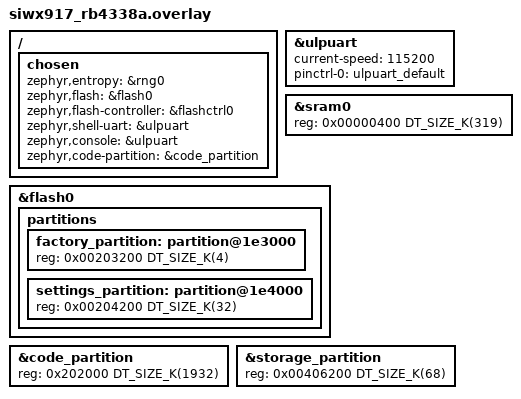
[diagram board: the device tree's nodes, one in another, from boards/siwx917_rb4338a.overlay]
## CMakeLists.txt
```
#
# Copyright (c) 2025 Project CHIP Authors
#
# Licensed under the Apache License, Version 2.0 (the "License");
# you may not use this file except in compliance with the License.
# You may obtain a copy of the License at
#
# http://www.apache.org/licenses/LICENSE-2.0
#
# Unless required by applicable law or agreed to in writing, software
# distributed under the License is distributed on an "AS IS" BASIS,
# WITHOUT WARRANTIES OR CONDITIONS OF ANY KIND, either express or implied.
# See the License for the specific language governing permissions and
# limitations under the License.
#
cmake_minimum_required(VERSION 3.13.1)

get_filename_component(CHIP_ROOT ${CMAKE_CURRENT_SOURCE_DIR}/../third_party/connectedhomeip REALPATH)
get_filename_component(GEN_DIR ${CHIP_ROOT}/zzz_generated/ REALPATH)
get_filename_component(ZEPHYR_PLATFORM_COMMON ${CHIP_ROOT}/examples/platform/silabs/zephyr REALPATH)
get_filename_component(SILABS_LIGHTING_COMMON ${CHIP_ROOT}/examples/lighting-app/silabs REALPATH)
get_filename_component(ALL_CLUSTERS_COMMON_DIR ${CHIP_ROOT}/examples/all-clusters-app/all-clusters-common REALPATH)


# Need this as wiseconnect abstraction is causing a build failure
add_definitions(-DMBEDTLS_X509_REMOVE_INFO )

list(APPEND ZEPHYR_EXTRA_MODULES ${CHIP_ROOT}/config/silabs)
find_package(Zephyr HINTS $ENV{ZEPHYR_BASE})

# -Wmaybe-uninitialized has too many false positives, including on std::optional
# and chip::Optional.  Make it nonfatal.
#
# See https://gcc.gnu.org/bugzilla/show_bug.cgi?id=80635
target_compile_options(app PRIVATE -Werror -Wno-error=maybe-uninitialized)
target_compile_options(app PRIVATE -Werror -Wno-error=format)

project(matter-zephyr-light)

include(${CHIP_ROOT}/config/silabs/app/enable-gnu-std.cmake)
include(${CHIP_ROOT}/src/app/chip_data_model.cmake)

target_include_directories(app
    PRIVATE
    include
    ${ZEPHYR_PLATFORM_COMMON}
)

target_sources(app
    PRIVATE
    src/AppTask.cpp
    src/DeviceCallbacks.cpp
    ../include/CHIPProjectConfig.h
    ${ZEPHYR_PLATFORM_COMMON}/main.cpp
    ${ZEPHYR_PLATFORM_COMMON}/AppTaskBase.cpp
    ${ZEPHYR_PLATFORM_COMMON}/AppTaskZephyr.cpp
    ${ZEPHYR_PLATFORM_COMMON}/CHIPDeviceManager.cpp
    ${ZEPHYR_PLATFORM_COMMON}/CommonDeviceCallbacks.cpp
    ${ZEPHYR_PLATFORM_COMMON}/ZclCallbacks.cpp
)

# TODO Implement OTA support
if(CONFIG_CHIP_OTA_REQUESTOR)
    # target_sources(app PRIVATE
    #                 ${EXAMPLE_PLATFORM_SILABS_COMMON_DIR}/ota_requestor/source/OTARequestorInitiatorCommon.cpp
    #                 ${EXAMPLE_PLATFORM_SILABS_COMMON_DIR}/ota_requestor/source/OTARequestorInitiatorZephyr.cpp
    # )
    # target_include_directories(app PRIVATE
    #                 ${EXAMPLE_PLATFORM_SILABS_COMMON_DIR}/ota_requestor/include/
    # )
endif()

if(CONFIG_CHIP_WIFI)
  chip_configure_data_model(app INCLUDE_SERVER
      ZAP_FILE ${SILABS_LIGHTING_COMMON}/data_model/lighting-wifi-app.zap
  )
else()
  chip_configure_data_model(app INCLUDE_SERVER
      ZAP_FILE ${SILABS_LIGHTING_COMMON}/data_model/lighting-thread-app.zap
  )
endif()

if(CONFIG_CHIP_LIB_SHELL)
    target_compile_definitions(app PRIVATE ENABLE_CHIP_SHELL)
    target_include_directories(app PRIVATE 
                               ${CHIP_ROOT}/examples/shell/shell_common/include
                               ${ZEPHYR_PLATFORM_COMMON}/include
    )
    target_sources(app PRIVATE
                   ${ZEPHYR_PLATFORM_COMMON}/AppCLIZephyr.cpp
                   ${CHIP_ROOT}/examples/shell/shell_common/cmd_misc.cpp
                   ${CHIP_ROOT}/examples/shell/shell_common/cmd_otcli.cpp
                   ${CHIP_ROOT}/examples/shell/shell_common/cmd_server.cpp
    )
endif()
```

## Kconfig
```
#
#    Copyright (c) 2025 Project CHIP Authors
#
#    Licensed under the Apache License, Version 2.0 (the "License");
#    you may not use this file except in compliance with the License.
#    You may obtain a copy of the License at
#
#        http://www.apache.org/licenses/LICENSE-2.0
#
#    Unless required by applicable law or agreed to in writing, software
#    distributed under the License is distributed on an "AS IS" BASIS,
#    WITHOUT WARRANTIES OR CONDITIONS OF ANY KIND, either express or implied.
#    See the License for the specific language governing permissions and
#    limitations under the License.
#
mainmenu "Matter Silabs Lighting Example Application"

# Sample configuration used for Thread networking
if NET_L2_OPENTHREAD
choice OPENTHREAD_DEVICE_TYPE
	default OPENTHREAD_FTD
endchoice
endif # NET_L2_OPENTHREAD

choice POSIX_AEP_CHOICE
	default POSIX_AEP_CHOICE_BASE
endchoice

rsource "../../../../config/silabs/Kconfig.defaults"
rsource "../../../../config/silabs/Kconfig"
source "Kconfig.zephyr"
```

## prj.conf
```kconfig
#
#    Copyright (c) 2025 Project CHIP Authors
#
#    Licensed under the Apache License, Version 2.0 (the "License");
#    you may not use this file except in compliance with the License.
#    You may obtain a copy of the License at
#
#        http://www.apache.org/licenses/LICENSE-2.0
#
#    Unless required by applicable law or agreed to in writing, software
#    distributed under the License is distributed on an "AS IS" BASIS,
#    WITHOUT WARRANTIES OR CONDITIONS OF ANY KIND, either express or implied.
#    See the License for the specific language governing permissions and
#    limitations under the License.
#

# This sample uses Kconfig.defaults to set options common for all
# samples. This file should contain only options specific for this sample
# or overrides of default values.

# Enable CHIP
CONFIG_CHIP=y
CONFIG_CHIP_PROJECT_CONFIG="../include/CHIPProjectConfig.h"
# 32773 == 0x8005 (example lighting-app)
CONFIG_CHIP_DEVICE_PRODUCT_ID=32773
CONFIG_STD_CPP17=y

CONFIG_GPIO=y

# Enable Matter extended announcement and increase duration to 1 hour.
CONFIG_CHIP_ENABLE_PAIRING_AUTOSTART=y
CONFIG_CHIP_BLE_EXT_ADVERTISING=y
CONFIG_CHIP_BLE_ADVERTISING_DURATION=60
CONFIG_MATTER_LOG_LEVEL_ERR=y

CONFIG_LOG_MODE_MINIMAL=n
CONFIG_LOG_MODE_DEFERRED=y
CONFIG_LOG_BUFFER_SIZE=8192

# CONFIG_IEEE802154_SILABS_EFR32_DRIVER_LOG_LEVEL=3
# CONFIG_OPENTHREAD_DEBUG=y
# CONFIG_OPENTHREAD_LOG_LEVEL_DEBG=y

CONFIG_OPENTHREAD_MANUAL_START=y
CONFIG_OPENTHREAD_OPERATIONAL_DATASET_AUTO_INIT=n
#CONFIG_OPENTHREAD_DEBUG=y
CONFIG_OPENTHREAD_LOG_LEVEL_INFO=y
CONFIG_OPENTHREAD_MLR=y
CONFIG_OPENTHREAD_SLAAC=y
CONFIG_OPENTHREAD_ENABLE_SERVICE=y
CONFIG_OPENTHREAD_THREAD_PREEMPTIVE=y
CONFIG_CHIP_TASK_PRIORITY=10
CONFIG_DNS_SD=y

# Needed for 917
CONFIG_NVS_INIT_BAD_MEMORY_REGION=y

CONFIG_SYSTEM_WORKQUEUE_STACK_SIZE=4096
CONFIG_MAIN_STACK_SIZE=8192
CONFIG_MBEDTLS_HEAP_SIZE=16384
CONFIG_SHELL_STACK_SIZE=4096
CONFIG_SHELL_THREAD_PRIORITY_OVERRIDE=y
CONFIG_SHELL_THREAD_PRIORITY=11
CONFIG_SHELL_BACKEND_SERIAL_LOG_MESSAGE_QUEUE_SIZE=2048

CONFIG_LOG_PROCESS_THREAD_CUSTOM_PRIORITY=y
CONFIG_LOG_PROCESS_THREAD_PRIORITY=12

CONFIG_UART_ASYNC_API=y

#CONFIG_MBEDTLS_CIPHER_GCM_ENABLED=y
CONFIG_SECURE_STORAGE_ITS_TRANSFORM_AEAD_SCHEME_AES_GCM=y
CONFIG_CHIP_LIB_SHELL=y

CONFIG_BT_HOST_CRYPTO=y

CONFIG_NET_IF_MCAST_IPV6_ADDR_COUNT=5

CONFIG_BT_RECV_WORKQ_BT=n
# TEMP FIX FOR NVS DELAYS with 917
CONFIG_NVS_LOOKUP_CACHE=y
CONFIG_NVS_LOOKUP_CACHE_SIZE=1024

# Bluetooth Low Energy configuration
CONFIG_BT_DEVICE_NAME="MatterLight"

# Reduce application size
CONFIG_USE_SEGGER_RTT=n

# Avoid getopt multiple-definition conflict between newlib nano and Zephyr's POSIX C lib extension.
# Newlib already provides getopt, strnlen, gmtime_r, strtok_r, etc.
CONFIG_POSIX_AEP_CHOICE_NONE=y

# CHIP's libCHIP.a uses thread_local storage (e.g. ErrorStr.cpp) which requires __aeabi_read_tp
CONFIG_THREAD_LOCAL_STORAGE=y
```

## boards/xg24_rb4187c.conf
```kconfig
#
# Copyright 2025, Silicon Laboratories Inc.
#

# OS
CONFIG_MAIN_STACK_SIZE=8192
# CONFIG_NO_OPTIMIZATIONS=y
CONFIG_THREAD_LOCAL_STORAGE=y

# CPP library
CONFIG_CPP=y

# Silicon Labs Openthread Settings
CONFIG_NET_L2_OPENTHREAD=n
CONFIG_SILABS_SISDK_OPENTHREAD_EFR32=y

CONFIG_SILABS_SISDK_RAIL_MULTIPROTOCOL=y
CONFIG_SIZE_OPTIMIZATIONS=y
CONFIG_OPENTHREAD_SYS_INIT_PRIORITY=60
# Shell
CONFIG_SHELL=y
CONFIG_SHELL_ARGC_MAX=26
CONFIG_SHELL_CMD_BUFF_SIZE=512
CONFIG_SHELL_STACK_SIZE=5120

# Enable OpenThread features set
CONFIG_OPENTHREAD_THREAD_VERSION_1_4=y
CONFIG_OPENTHREAD_SHELL=y


# CONFIG_ZEPHYR_PICOLIBC_MODULE=n
# CONFIG_HAS_SEGGER_RTT=n
```

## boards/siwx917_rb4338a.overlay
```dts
/*
 *    Copyright (c) 2025 Project CHIP Authors
 *    All rights reserved.
 *
 *    Licensed under the Apache License, Version 2.0 (the "License");
 *    you may not use this file except in compliance with the License.
 *    You may obtain a copy of the License at
 *
 *        http://www.apache.org/licenses/LICENSE-2.0
 *
 *    Unless required by applicable law or agreed to in writing, software
 *    distributed under the License is distributed on an "AS IS" BASIS
 *    WITHOUT WARRANTIES OR CONDITIONS OF ANY KIND, either express or implied.
 *    See the License for the specific language governing permissions and
 *    limitations under the License.
 */

/ {
	chosen {
		zephyr,entropy = &rng0;
		zephyr,flash = &flash0;
		zephyr,flash-controller = &flashctrl0;
		zephyr,shell-uart = &ulpuart;
		zephyr,console = &ulpuart;
		zephyr,code-partition = &code_partition;
	};
};

&ulpuart {
	status = "okay";
	current-speed = <115200>;
	pinctrl-0 = <&ulpuart_default>;
	pinctrl-names = "default";
};



&sram0 {
    status = "okay";
    reg = <0x00000400 DT_SIZE_K(319)>;
};


/*
&flash0 {
    status = "okay";
    partitions {
        code_partition: partition@0 {
			reg = <0x0000000 DT_SIZE_K(2000)>;
			label = "code_partition";
		};

        factory_partition: partition@1f4000 {
            label = "factory-data";
            reg = <0x001f400 DT_SIZE_K(4)>;
        };

        settings_partition: partition@1f500 {
            label = "settings_partition";
            reg = <0x001f5000 DT_SIZE_K(4)>;
        };

        storage_partition: partition@1f6000 {
			reg = <0x001f6000 DT_SIZE_K(32)>;
			label = "storage";
		};
    };
};

*/

&flash0 {
        partitions {
                factory_partition: partition@1e3000 {
                        reg = <0x00203200 DT_SIZE_K(4)>;
                };

                settings_partition: partition@1e4000 {
                        reg = <0x00204200 DT_SIZE_K(32)>;
                };
        };
};

&code_partition {
       reg = <0x202000 DT_SIZE_K(1932)>;
};


&storage_partition {
        reg = <0x00406200 DT_SIZE_K(68)>;
};
```

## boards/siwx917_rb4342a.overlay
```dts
/*
 *    Copyright (c) 2025 Project CHIP Authors
 *    All rights reserved.
 *
 *    Licensed under the Apache License, Version 2.0 (the "License");
 *    you may not use this file except in compliance with the License.
 *    You may obtain a copy of the License at
 *
 *        http://www.apache.org/licenses/LICENSE-2.0
 *
 *    Unless required by applicable law or agreed to in writing, software
 *    distributed under the License is distributed on an "AS IS" BASIS
 *    WITHOUT WARRANTIES OR CONDITIONS OF ANY KIND, either express or implied.
 *    See the License for the specific language governing permissions and
 *    limitations under the License.
 */

/ {
	chosen {
		zephyr,entropy = &rng0;
		zephyr,flash = &flash0;
		zephyr,flash-controller = &flashctrl0;
		zephyr,shell-uart = &ulpuart;
		zephyr,console = &ulpuart;
		zephyr,code-partition = &code_partition;
	};
};

&ulpuart {
	status = "okay";
	current-speed = <115200>;
	pinctrl-0 = <&ulpuart_default>;
	pinctrl-names = "default";
};



&sram0 {
    status = "okay";
    reg = <0x00000400 DT_SIZE_K(319)>;
};

&flash0 {
        partitions {
                factory_partition: partition@1e3000 {
                        reg = <0x00203200 DT_SIZE_K(4)>;
                };

                settings_partition: partition@1e4000 {
                        reg = <0x00204200 DT_SIZE_K(32)>;
                };
        };
};

&code_partition {
       reg = <0x202000 DT_SIZE_K(1932)>;
};


&storage_partition {
        reg = <0x00406200 DT_SIZE_K(92)>;
};
```

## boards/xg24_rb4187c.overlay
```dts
/*
 *    Copyright (c) 2025 Project CHIP Authors
 *    All rights reserved.
 *
 *    Licensed under the Apache License, Version 2.0 (the "License");
 *    you may not use this file except in compliance with the License.
 *    You may obtain a copy of the License at
 *
 *        http://www.apache.org/licenses/LICENSE-2.0
 *
 *    Unless required by applicable law or agreed to in writing, software
 *    distributed under the License is distributed on an "AS IS" BASIS
 *    WITHOUT WARRANTIES OR CONDITIONS OF ANY KIND, either express or implied.
 *    See the License for the specific language governing permissions and
 *    limitations under the License.
 */



&flash0 {
    partitions {
        factory_partition: partition@138000 {
                reg = <0x00138000 DT_SIZE_K(32)>;
        };
        settings_partition: partition@140000 {
                reg = <0x00140000 DT_SIZE_K(32)>;
        };
    };
};

&slot0_partition {
    reg = <0x0000c000 DT_SIZE_K(1200)>;
};

&slot1_partition {
    reg = <0x00141000 DT_SIZE_K(4)>;
};

/* Set 32 kB of storage at the end of the 1536 kB of flash */
&storage_partition {
    reg = <0x00142000 DT_SIZE_K(40)>;
};
```

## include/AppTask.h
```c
/*
 *
 *    Copyright (c) 2025 Project CHIP Authors
 *    All rights reserved.
 *
 *    Licensed under the Apache License, Version 2.0 (the "License");
 *    you may not use this file except in compliance with the License.
 *    You may obtain a copy of the License at
 *
 *        http://www.apache.org/licenses/LICENSE-2.0
 *
 *    Unless required by applicable law or agreed to in writing, software
 *    distributed under the License is distributed on an "AS IS" BASIS,
 *    WITHOUT WARRANTIES OR CONDITIONS OF ANY KIND, either express or implied.
 *    See the License for the specific language governing permissions and
 *    limitations under the License.
 */

#pragma once

#include "AppTaskZephyr.h"

class AppTask : public chip::Zephyr::App::AppTaskZephyr
{
public:
    ~AppTask() override{};
    void PreInitMatterStack(void) override;
    void PostInitMatterStack(void) override;
    void PostInitMatterServerInstance(void) override;
    // This returns an instance of this class.
    static AppTask & GetDefaultInstance();

private:
    static AppTask sAppTask;
};

/**
 * Returns the application-specific implementation of the AppTaskBase object.
 *
 * Applications can use this to gain access to features of the AppTaskBase
 * that are specific to the selected application.
 */
chip::Zephyr::App::AppTaskBase & GetAppTask();

/**
 * Set the state of LED1 to reflect the on/off state.
 * This is a no-op if LED1 is not available on the board.
 *
 * @param state true to turn the LED on, false to turn it off.
 */
void SetLed1OnOffState(bool state);
```

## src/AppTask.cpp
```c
/*
 *
 *    Copyright (c) 2025 Project CHIP Authors
 *    All rights reserved.
 *
 *    Licensed under the Apache License, Version 2.0 (the "License");
 *    you may not use this file except in compliance with the License.
 *    You may obtain a copy of the License at
 *
 *        http://www.apache.org/licenses/LICENSE-2.0
 *
 *    Unless required by applicable law or agreed to in writing, software
 *    distributed under the License is distributed on an "AS IS" BASIS,
 *    WITHOUT WARRANTIES OR CONDITIONS OF ANY KIND, either express or implied.
 *    See the License for the specific language governing permissions and
 *    limitations under the License.
 */

#include "AppTask.h"
#include "CHIPDeviceManager.h"

#include <app-common/zap-generated/ids/Attributes.h>
#include <app-common/zap-generated/ids/Clusters.h>
#include <app/clusters/on-off-server/on-off-server.h>
#include <app/server/Server.h>
#include <app/util/attribute-storage.h>
#include <platform/CHIPDeviceLayer.h>

#include <zephyr/drivers/gpio.h>
#include <zephyr/kernel.h>
#include <zephyr/logging/log.h>

#ifdef MATTER_DM_PLUGIN_BINDING
#include "binding-handler.h"
#endif

LOG_MODULE_DECLARE(app, CONFIG_CHIP_APP_LOG_LEVEL);

using namespace chip;
using namespace chip::DeviceLayer;
using namespace chip::app::Clusters;

namespace {
constexpr EndpointId kLightEndpointId = 1;
} // namespace

/* -------------------------------------------------------------------------- */
/*                          LED devicetree bindings                           */
/* -------------------------------------------------------------------------- */

#if DT_NODE_EXISTS(DT_ALIAS(led0))
#define HAS_LED0 1
static const struct gpio_dt_spec sLed0 = GPIO_DT_SPEC_GET(DT_ALIAS(led0), gpios);
static struct k_timer sLed0BlinkTimer;
static bool sLed0State;
#endif

#if DT_NODE_EXISTS(DT_ALIAS(led1))
#define HAS_LED1 1
static const struct gpio_dt_spec sLed1 = GPIO_DT_SPEC_GET(DT_ALIAS(led1), gpios);
#endif

/* -------------------------------------------------------------------------- */
/*                        Button devicetree bindings                          */
/* -------------------------------------------------------------------------- */

#if DT_NODE_EXISTS(DT_ALIAS(sw0))
#define HAS_BUTTON0 1
static const struct gpio_dt_spec sButton0 = GPIO_DT_SPEC_GET(DT_ALIAS(sw0), gpios);
static struct gpio_callback sButton0CbData;
static struct k_work_delayable sFactoryResetWarningWork;
static struct k_work_delayable sFactoryResetTriggerWork;
#endif

#if DT_NODE_EXISTS(DT_ALIAS(sw1))
#define HAS_BUTTON1 1
static const struct gpio_dt_spec sButton1 = GPIO_DT_SPEC_GET(DT_ALIAS(sw1), gpios);
static struct gpio_callback sButton1CbData;
static struct k_work sToggleOnOffWork;
#endif

/* -------------------------------------------------------------------------- */
/*                           LED helper functions                             */
/* -------------------------------------------------------------------------- */

#ifdef HAS_LED0
static void Led0BlinkTimerHandler(struct k_timer * timer)
{
    sLed0State = !sLed0State;
    gpio_pin_set_dt(&sLed0, static_cast<int>(sLed0State));
}
#endif

/* -------------------------------------------------------------------------- */
/*                             Button callbacks                               */
/* -------------------------------------------------------------------------- */

#ifdef HAS_BUTTON0
static void FactoryResetWarningWorkHandler(struct k_work * work)
{
    LOG_INF("Keep holding to factory reset in 5 seconds. Release to cancel.");
}

static void FactoryResetTriggerWorkHandler(struct k_work * work)
{
    LOG_INF("Factory reset triggered");
    chip::Server::GetInstance().ScheduleFactoryReset();
}

static void Button0PressedHandler(const struct device * dev, struct gpio_callback * cb, uint32_t pins)
{
    if (gpio_pin_get_dt(&sButton0) > 0)
    {
        k_work_schedule(&sFactoryResetWarningWork, K_SECONDS(2));
        k_work_schedule(&sFactoryResetTriggerWork, K_SECONDS(7));
    }
    else
    {
        bool wasPending = k_work_cancel_delayable(&sFactoryResetTriggerWork) != 0;
        k_work_cancel_delayable(&sFactoryResetWarningWork);
        if (wasPending)
        {
            LOG_INF("Factory reset canceled");
        }
    }
}
#endif

#ifdef HAS_BUTTON1
static void ToggleOnOffWorkHandler(struct k_work * work)
{
    bool currentValue;
    OnOffServer::Instance().getOnOffValue(1, &currentValue);
    OnOffServer::Instance().setOnOffValue(1, !currentValue, false);
}

static void Button1PressedHandler(const struct device * dev, struct gpio_callback * cb, uint32_t pins)
{
    k_work_submit(&sToggleOnOffWork);
}
#endif

/* -------------------------------------------------------------------------- */
/*                          AppTask implementation                            */
/* -------------------------------------------------------------------------- */

void AppTask::PreInitMatterStack()
{
    ChipLogProgress(DeviceLayer, "Welcome to Zephyr Matter Light Demo App");

#ifdef HAS_LED0
    if (gpio_is_ready_dt(&sLed0))
    {
        gpio_pin_configure_dt(&sLed0, GPIO_OUTPUT_INACTIVE);
    }
    k_timer_init(&sLed0BlinkTimer, Led0BlinkTimerHandler, nullptr);
#endif

#ifdef HAS_LED1
    if (gpio_is_ready_dt(&sLed1))
    {
        gpio_pin_configure_dt(&sLed1, GPIO_OUTPUT_INACTIVE);
    }
#endif

#ifdef HAS_BUTTON0
    k_work_init_delayable(&sFactoryResetWarningWork, FactoryResetWarningWorkHandler);
    k_work_init_delayable(&sFactoryResetTriggerWork, FactoryResetTriggerWorkHandler);

    if (gpio_is_ready_dt(&sButton0))
    {
        gpio_pin_configure_dt(&sButton0, GPIO_INPUT);
        gpio_pin_interrupt_configure_dt(&sButton0, GPIO_INT_EDGE_BOTH);
        gpio_init_callback(&sButton0CbData, Button0PressedHandler, BIT(sButton0.pin));
        gpio_add_callback(sButton0.port, &sButton0CbData);
    }
#endif

#ifdef HAS_BUTTON1
    k_work_init(&sToggleOnOffWork, ToggleOnOffWorkHandler);

    if (gpio_is_ready_dt(&sButton1))
    {
        gpio_pin_configure_dt(&sButton1, GPIO_INPUT);
        gpio_pin_interrupt_configure_dt(&sButton1, GPIO_INT_EDGE_TO_ACTIVE);
        gpio_init_callback(&sButton1CbData, Button1PressedHandler, BIT(sButton1.pin));
        gpio_add_callback(sButton1.port, &sButton1CbData);
    }
#endif
}

void AppTask::PostInitMatterStack()
{
#ifdef MATTER_DM_PLUGIN_BINDING
    CHIP_ERROR err = InitBindingHandlers();
    if (err != CHIP_NO_ERROR)
    {
        ChipLogError(DeviceLayer, "InitBindingHandlers failed: %" CHIP_ERROR_FORMAT, err.Format());
    }
#endif

#ifdef HAS_LED0
    if (ConnectivityMgr().IsBLEAdvertisingEnabled())
    {
        sLed0State = false;
        k_timer_start(&sLed0BlinkTimer, K_MSEC(500), K_MSEC(500));
    }
#endif
}

void AppTask::PostInitMatterServerInstance() {}

AppTask & AppTask::GetDefaultInstance()
{
    static AppTask sAppTask;
    return sAppTask;
}

chip::Zephyr::App::AppTaskBase & chip::Zephyr::App::GetAppTask()
{
    return AppTask::GetDefaultInstance();
}

void SetLed1OnOffState(bool state)
{
#ifdef HAS_LED1
    gpio_pin_set_dt(&sLed1, static_cast<int>(state));
#else
    (void) state;
#endif
}
```

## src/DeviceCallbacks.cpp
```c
/*
 *
 *    Copyright (c) 2024 Project CHIP Authors
 *    All rights reserved.
 *
 *    Licensed under the Apache License, Version 2.0 (the "License");
 *    you may not use this file except in compliance with the License.
 *    You may obtain a copy of the License at
 *
 *        http://www.apache.org/licenses/LICENSE-2.0
 *
 *    Unless required by applicable law or agreed to in writing, software
 *    distributed under the License is distributed on an "AS IS" BASIS,
 *    WITHOUT WARRANTIES OR CONDITIONS OF ANY KIND, either express or implied.
 *    See the License for the specific language governing permissions and
 *    limitations under the License.
 */

#include <lib/support/logging/CHIPLogging.h>

#include "AppTask.h"
#include "DeviceCallbacks.h"
#if CONFIG_ENABLE_FEEDBACK
#include "UserInterfaceFeedback.h"
#endif

#include <app-common/zap-generated/ids/Attributes.h>
#include <app-common/zap-generated/ids/Clusters.h>

using namespace ::chip;
using namespace ::chip::app::Clusters;

void LightingApp::DeviceCallbacks::PostAttributeChangeCallback(chip::EndpointId endpoint, chip::ClusterId clusterId,
                                                               chip::AttributeId attributeId, uint8_t type, uint16_t size,
                                                               uint8_t * value)
{
    if (clusterId == OnOff::Id)
    {
        if (attributeId != OnOff::Attributes::OnOff::Id)
        {
            ChipLogProgress(Zcl, "Unknown attribute ID: " ChipLogFormatMEI, ChipLogValueMEI(attributeId));
            return;
        }
        if (value != nullptr)
        {
            SetLed1OnOffState(*value != 0);
        }
    }
    else if (clusterId == LevelControl::Id)
    {
        if (attributeId != LevelControl::Attributes::CurrentLevel::Id)
        {
            ChipLogProgress(Zcl, "Unknown attribute ID: " ChipLogFormatMEI, ChipLogValueMEI(attributeId));
            return;
        }
#if LIGHTING_MANAGER_ENABLE_DIMMABLE_LED
        if (*value > 1 && *value < 254)
        {
            ChipLogProgress(Zcl, "Setting value: %d", *value);
            // The cluster attribute value will be read in RestoreState and the proper action will be taken: e.g. ApplyDim.
#if CONFIG_ENABLE_FEEDBACK
            FeedbackMgr().RestoreState();
#endif
        }
#endif
    }
    else if (clusterId == ColorControl::Id)
    {
        ChipLogProgress(Zcl, "Color Control attribute ID: " ChipLogFormatMEI " Type: %u Value: %u, length %u",
                        ChipLogValueMEI(attributeId), type, *value, size);

        // WIP Apply attribute change to Light
    }
    else
    {
        ChipLogProgress(Zcl, "Unknown attribute ID: " ChipLogFormatMEI, ChipLogValueMEI(attributeId));
    }
}

chip::DeviceManager::CHIPDeviceManagerCallbacks & chip::Zephyr::App::GetDeviceCallbacks()
{
    static LightingApp::DeviceCallbacks sDeviceCallbacks;
    return sDeviceCallbacks;
}
```
